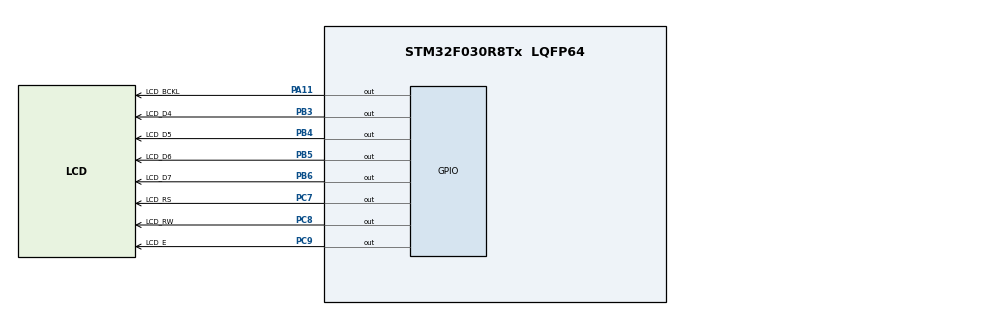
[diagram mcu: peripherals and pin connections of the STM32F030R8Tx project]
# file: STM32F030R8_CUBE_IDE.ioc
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Mcu.Family=STM32F0
Mcu.Name=STM32F030R8Tx
Mcu.Package=LQFP64
PA11.GPIO_Label=LCD_BCKL
PA11.Signal=GPIO_Output
PB3.GPIO_Label=LCD_D4
PB3.Signal=GPIO_Output
PB4.GPIO_Label=LCD_D5
PB4.Signal=GPIO_Output
PB5.GPIO_Label=LCD_D6
PB5.Signal=GPIO_Output
PB6.GPIO_Label=LCD_D7
PB6.Signal=GPIO_Output
PC7.GPIO_Label=LCD_RS
PC7.Signal=GPIO_Output
PC8.GPIO_Label=LCD_RW
PC8.Signal=GPIO_Output
PC9.GPIO_Label=LCD_E
PC9.Signal=GPIO_Output
ProjectManager.HeapSize=0x200
ProjectManager.StackSize=0x400
ProjectManager.TargetToolchain=STM32CubeIDE
RCC.AHBFreq_Value=48000000
RCC.APB1Freq_Value=48000000
RCC.APB1TimFreq_Value=48000000
RCC.HCLKFreq_Value=48000000
RCC.PLLMUL=RCC_PLL_MUL12
RCC.SYSCLKFreq_VALUE=48000000
RCC.SYSCLKSource=RCC_SYSCLKSOURCE_PLLCLK
board=custom

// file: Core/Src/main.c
/* USER CODE BEGIN Header */
/**
  ******************************************************************************
  * @file           : main.c
  * @brief          : Main program body
  ******************************************************************************
  * @attention
  *
  * Copyright (c) 2023 STMicroelectronics.
  * All rights reserved.
  *
  * This software is licensed under terms that can be found in the LICENSE file
  * in the root directory of this software component.
  * If no LICENSE file comes with this software, it is provided AS-IS.
  *
  ******************************************************************************
  */
/* USER CODE END Header */
#include "main.h"

/* USER CODE BEGIN Includes */
//#include "lcd_hd44780.h"
// #include "tim_delay.h"
#include "hw_test_main.h"
/* USER CODE END Includes */

void SystemClock_Config(void);
static void MX_GPIO_Init(void);

int main(void)
{

  /* MCU Configuration--------------------------------------------------------*/

  /* Reset of all peripherals, Initializes the Flash interface and the Systick. */
  LL_APB1_GRP2_EnableClock(LL_APB1_GRP2_PERIPH_SYSCFG);
  LL_APB1_GRP1_EnableClock(LL_APB1_GRP1_PERIPH_PWR);

  /* SysTick_IRQn interrupt configuration */
  NVIC_SetPriority(SysTick_IRQn, 3);

  /* Configure the system clock */
  SystemClock_Config();

  /* Initialize all configured peripherals */
  MX_GPIO_Init();
  /* USER CODE BEGIN 2 */
  // lcd_init();
  // lcd_char('G');
  // delay_ms(2000);
  // lcd_cls();
  // lcd_def_char(pol_e,Pol_e);
  // lcd_load_char_bank(&char_bank_1);
  // lcd_char(pol_e);
  // lcd_char(pol_o);
  // lcd_char(zn_wody);
  // lcd_char('l');
  /* USER CODE END 2 */

  /* Infinite loop */
  while (1)
  {
  main_hw_test();
  }
}

void SystemClock_Config(void)
{
  LL_FLASH_SetLatency(LL_FLASH_LATENCY_1);
  while(LL_FLASH_GetLatency() != LL_FLASH_LATENCY_1)
  {
  }
  LL_RCC_HSI_Enable();

   /* Wait till HSI is ready */
  while(LL_RCC_HSI_IsReady() != 1)
  {

  }
  LL_RCC_HSI_SetCalibTrimming(16);
  LL_RCC_PLL_ConfigDomain_SYS(LL_RCC_PLLSOURCE_HSI_DIV_2, LL_RCC_PLL_MUL_12);
  LL_RCC_PLL_Enable();

   /* Wait till PLL is ready */
  while(LL_RCC_PLL_IsReady() != 1)
  {

  }
  LL_RCC_SetAHBPrescaler(LL_RCC_SYSCLK_DIV_1);
  LL_RCC_SetAPB1Prescaler(LL_RCC_APB1_DIV_1);
  LL_RCC_SetSysClkSource(LL_RCC_SYS_CLKSOURCE_PLL);

   /* Wait till System clock is ready */
  while(LL_RCC_GetSysClkSource() != LL_RCC_SYS_CLKSOURCE_STATUS_PLL)
  {

  }
  LL_Init1msTick(48000000);
  LL_SetSystemCoreClock(48000000);
}

static void MX_GPIO_Init(void)
{
  LL_GPIO_InitTypeDef GPIO_InitStruct = {0};

  /* GPIO Ports Clock Enable */
  LL_AHB1_GRP1_EnableClock(LL_AHB1_GRP1_PERIPH_GPIOC);
  LL_AHB1_GRP1_EnableClock(LL_AHB1_GRP1_PERIPH_GPIOA);
  LL_AHB1_GRP1_EnableClock(LL_AHB1_GRP1_PERIPH_GPIOB);

  /**/
  LL_GPIO_ResetOutputPin(LCD_RS_GPIO_Port, LCD_RS_Pin);

  /**/
  LL_GPIO_ResetOutputPin(LCD_RW_GPIO_Port, LCD_RW_Pin);

  /**/
  LL_GPIO_ResetOutputPin(LCD_E_GPIO_Port, LCD_E_Pin);

  /**/
  LL_GPIO_ResetOutputPin(LCD_BCKL_GPIO_Port, LCD_BCKL_Pin);

  /**/
  LL_GPIO_ResetOutputPin(LCD_D4_GPIO_Port, LCD_D4_Pin);

  /**/
  LL_GPIO_ResetOutputPin(LCD_D5_GPIO_Port, LCD_D5_Pin);

  /**/
  LL_GPIO_ResetOutputPin(LCD_D6_GPIO_Port, LCD_D6_Pin);

  /**/
  LL_GPIO_ResetOutputPin(LCD_D7_GPIO_Port, LCD_D7_Pin);

  /**/
  GPIO_InitStruct.Pin = LCD_RS_Pin;
  GPIO_InitStruct.Mode = LL_GPIO_MODE_OUTPUT;
  GPIO_InitStruct.Speed = LL_GPIO_SPEED_FREQ_LOW;
  GPIO_InitStruct.OutputType = LL_GPIO_OUTPUT_PUSHPULL;
  GPIO_InitStruct.Pull = LL_GPIO_PULL_NO;
  LL_GPIO_Init(LCD_RS_GPIO_Port, &GPIO_InitStruct);

  /**/
  GPIO_InitStruct.Pin = LCD_RW_Pin;
  GPIO_InitStruct.Mode = LL_GPIO_MODE_OUTPUT;
  GPIO_InitStruct.Speed = LL_GPIO_SPEED_FREQ_LOW;
  GPIO_InitStruct.OutputType = LL_GPIO_OUTPUT_PUSHPULL;
  GPIO_InitStruct.Pull = LL_GPIO_PULL_NO;
  LL_GPIO_Init(LCD_RW_GPIO_Port, &GPIO_InitStruct);

  /**/
  GPIO_InitStruct.Pin = LCD_E_Pin;
  GPIO_InitStruct.Mode = LL_GPIO_MODE_OUTPUT;
  GPIO_InitStruct.Speed = LL_GPIO_SPEED_FREQ_LOW;
  GPIO_InitStruct.OutputType = LL_GPIO_OUTPUT_PUSHPULL;
  GPIO_InitStruct.Pull = LL_GPIO_PULL_NO;
  LL_GPIO_Init(LCD_E_GPIO_Port, &GPIO_InitStruct);

  /**/
  GPIO_InitStruct.Pin = LCD_BCKL_Pin;
  GPIO_InitStruct.Mode = LL_GPIO_MODE_OUTPUT;
  GPIO_InitStruct.Speed = LL_GPIO_SPEED_FREQ_LOW;
  GPIO_InitStruct.OutputType = LL_GPIO_OUTPUT_PUSHPULL;
  GPIO_InitStruct.Pull = LL_GPIO_PULL_NO;
  LL_GPIO_Init(LCD_BCKL_GPIO_Port, &GPIO_InitStruct);

  /**/
  GPIO_InitStruct.Pin = LCD_D4_Pin;
  GPIO_InitStruct.Mode = LL_GPIO_MODE_OUTPUT;
  GPIO_InitStruct.Speed = LL_GPIO_SPEED_FREQ_LOW;
  GPIO_InitStruct.OutputType = LL_GPIO_OUTPUT_PUSHPULL;
  GPIO_InitStruct.Pull = LL_GPIO_PULL_NO;
  LL_GPIO_Init(LCD_D4_GPIO_Port, &GPIO_InitStruct);

  /**/
  GPIO_InitStruct.Pin = LCD_D5_Pin;
  GPIO_InitStruct.Mode = LL_GPIO_MODE_OUTPUT;
  GPIO_InitStruct.Speed = LL_GPIO_SPEED_FREQ_LOW;
  GPIO_InitStruct.OutputType = LL_GPIO_OUTPUT_PUSHPULL;
  GPIO_InitStruct.Pull = LL_GPIO_PULL_NO;
  LL_GPIO_Init(LCD_D5_GPIO_Port, &GPIO_InitStruct);

  /**/
  GPIO_InitStruct.Pin = LCD_D6_Pin;
  GPIO_InitStruct.Mode = LL_GPIO_MODE_OUTPUT;
  GPIO_InitStruct.Speed = LL_GPIO_SPEED_FREQ_LOW;
  GPIO_InitStruct.OutputType = LL_GPIO_OUTPUT_PUSHPULL;
  GPIO_InitStruct.Pull = LL_GPIO_PULL_NO;
  LL_GPIO_Init(LCD_D6_GPIO_Port, &GPIO_InitStruct);

  /**/
  GPIO_InitStruct.Pin = LCD_D7_Pin;
  GPIO_InitStruct.Mode = LL_GPIO_MODE_OUTPUT;
  GPIO_InitStruct.Speed = LL_GPIO_SPEED_FREQ_LOW;
  GPIO_InitStruct.OutputType = LL_GPIO_OUTPUT_PUSHPULL;
  GPIO_InitStruct.Pull = LL_GPIO_PULL_NO;
  LL_GPIO_Init(LCD_D7_GPIO_Port, &GPIO_InitStruct);

}

void Error_Handler(void)
{
  __disable_irq();
  while (1)
  {
  }
}
